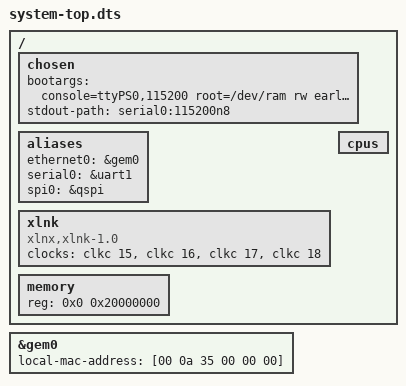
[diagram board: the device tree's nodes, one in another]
/*
 * CAUTION: This file is automatically generated by Xilinx.
 * Version:  
 * Today is: Wed Oct 25 10:43:29 2017
*/


/dts-v1/;
/include/ "zynq-7000.dtsi"
/include/ "pl.dtsi"
/include/ "pcw.dtsi"
/ {
	chosen {
		bootargs = "console=ttyPS0,115200 root=/dev/ram rw earlyprintk ip=none rootwait earlycon cma=256M";
		stdout-path = "serial0:115200n8";
	};
	aliases {
		ethernet0 = &gem0;
		serial0 = &uart1;
		spi0 = &qspi;
	};
	xlnk {
		compatible = "xlnx,xlnk-1.0";
		clock-names = "xclk0", "xclk1", "xclk2", "xclk3";
		clocks = <&clkc 15>, <&clkc 16>, <&clkc 17>, <&clkc 18>;
	};
	memory {
		device_type = "memory";
		reg = <0x0 0x20000000>;
	};
	cpus {
	};
};

&gem0 {
	local-mac-address = [00 0a 35 00 00 00];
};
